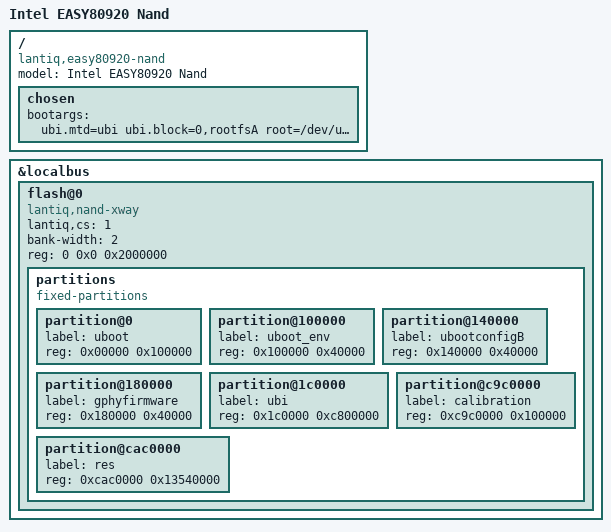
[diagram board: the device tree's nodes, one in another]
/dts-v1/;


#include "EASY80920.dtsi"

/ {
	compatible = "lantiq,easy80920-nand", "lantiq,easy80920", "lantiq,xway", "lantiq,vr9";
	model = "Intel EASY80920 Nand";

	chosen {
		bootargs = "ubi.mtd=ubi ubi.block=0,rootfsA root=/dev/ubiblock0_1";
	};
};

&localbus {
	flash@0 {
		compatible = "lantiq,nand-xway";
		lantiq,cs = <1>;
		bank-width = <2>;
		reg = <0 0x0 0x2000000>;

		partitions {
			compatible = "fixed-partitions";
			#address-cells = <1>;
			#size-cells = <1>;

			partition@0 {
				label = "uboot";
				reg = <0x00000 0x100000>; /* 1024 KB */
			};

			partition@100000 {
				label = "uboot_env";
				reg = <0x100000 0x40000>; /* 256 KB */
			};

			partition@140000 {
				label = "ubootconfigB";
				reg = <0x140000 0x40000>; /* 256 KB */
			};

			partition@180000 {
				label = "gphyfirmware";
				reg = <0x180000 0x40000>; /* 256 KB */
			};

			partition@1c0000 {
				label = "ubi";
				reg = <0x1c0000 0xc800000>;
			};

			partition@c9c0000 {
				label = "calibration";
				reg = <0xc9c0000 0x100000>;
			};

			partition@cac0000 {
				label = "res";
				reg = <0xcac0000 0x13540000>;
			};
		};
	};
};
